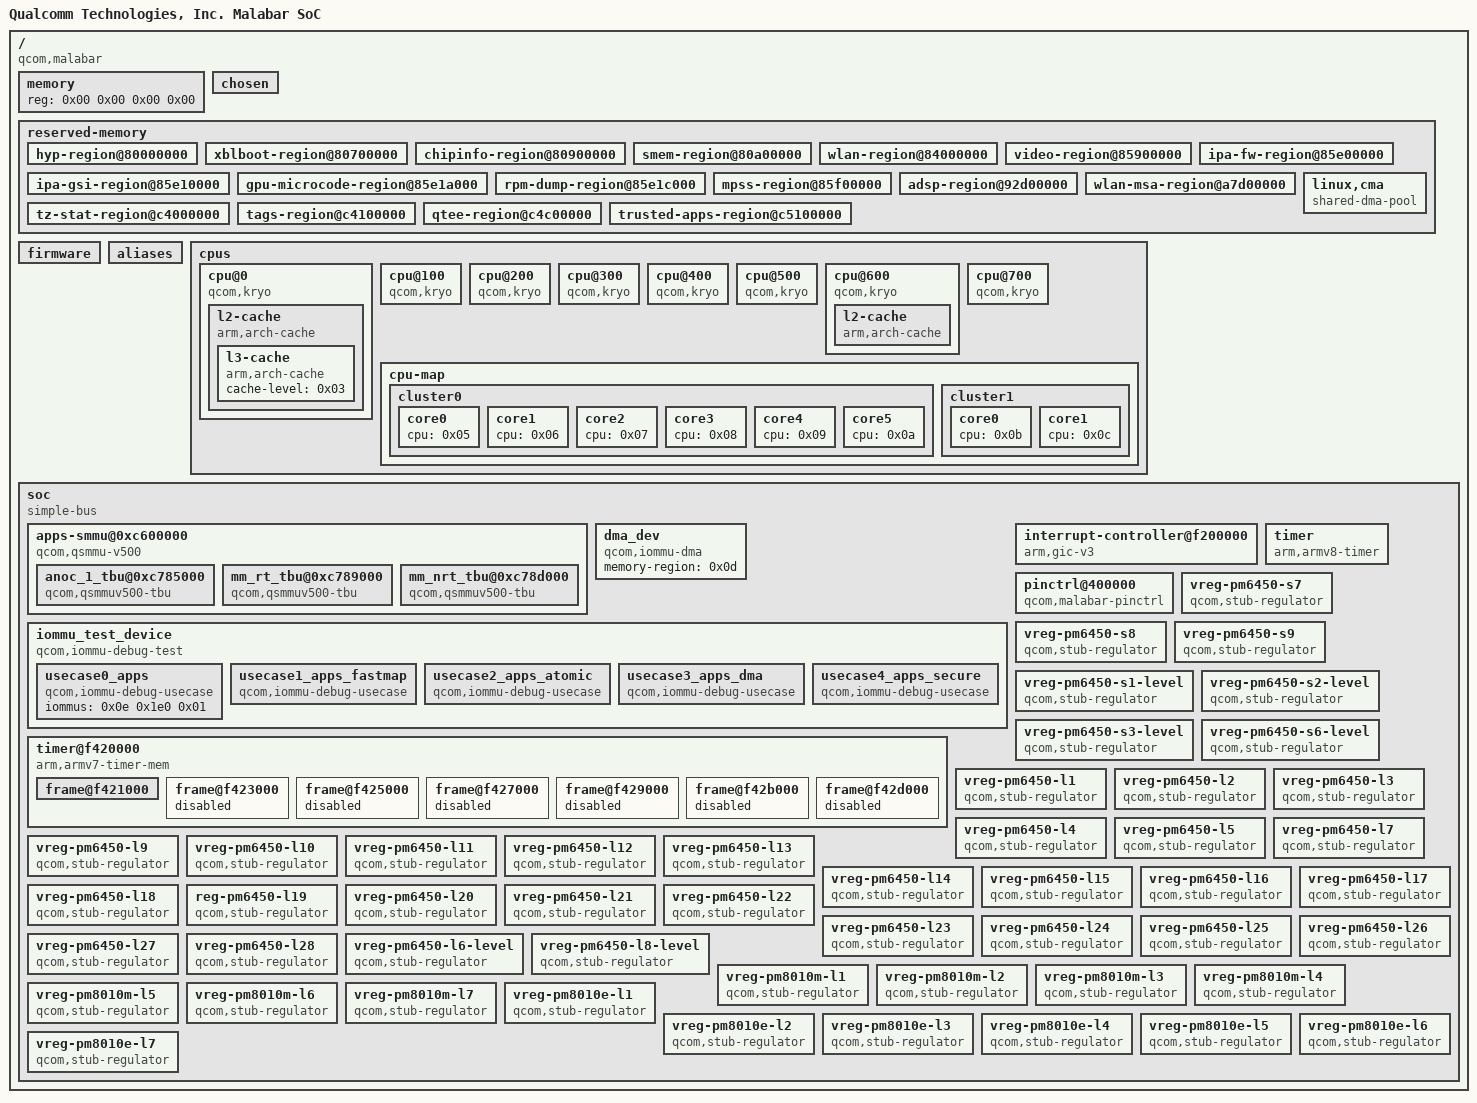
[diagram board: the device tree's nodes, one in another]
/dts-v1/;

/ {
	model = "Qualcomm Technologies, Inc. Malabar SoC";
	compatible = "qcom,malabar";
	qcom,msm-id = <0x2dd 0x10000>;
	interrupt-parent = <0x01>;
	#address-cells = <0x02>;
	#size-cells = <0x02>;
	qcom,board-id = <0x00 0x00>;

	memory {
		device_type = "memory";
		reg = <0x00 0x00 0x00 0x00>;
	};

	chosen {
		bootargs = "nokaslr kpti=0 log_buf_len=256K swiotlb=0 loop.max_part=7";
		phandle = <0x0f>;
	};

	reserved-memory {
		#address-cells = <0x02>;
		#size-cells = <0x02>;
		ranges;
		phandle = <0x10>;

		hyp-region@80000000 {
			reg = <0x00 0x80000000 0x00 0x700000>;
			no-map;
			phandle = <0x11>;
		};

		xblboot-region@80700000 {
			reg = <0x00 0x80700000 0x00 0x100000>;
			no-map;
			phandle = <0x12>;
		};

		chipinfo-region@80900000 {
			reg = <0x00 0x80900000 0x00 0x1000>;
			no-map;
			phandle = <0x13>;
		};

		smem-region@80a00000 {
			reg = <0x00 0x80a00000 0x00 0x200000>;
			no-map;
			phandle = <0x14>;
		};

		wlan-region@84000000 {
			reg = <0x00 0x84000000 0x00 0x1900000>;
			no-map;
			phandle = <0x15>;
		};

		video-region@85900000 {
			reg = <0x00 0x85900000 0x00 0x500000>;
			no-map;
			phandle = <0x16>;
		};

		ipa-fw-region@85e00000 {
			reg = <0x00 0x85e00000 0x00 0x10000>;
			no-map;
			phandle = <0x17>;
		};

		ipa-gsi-region@85e10000 {
			reg = <0x00 0x85e10000 0x00 0xa000>;
			no-map;
			phandle = <0x18>;
		};

		gpu-microcode-region@85e1a000 {
			reg = <0x00 0x85e1a000 0x00 0x2000>;
			no-map;
			phandle = <0x19>;
		};

		rpm-dump-region@85e1c000 {
			reg = <0x00 0x85e1c000 0x00 0x25800>;
			no-map;
			phandle = <0x1a>;
		};

		mpss-region@85f00000 {
			reg = <0x00 0x85f00000 0x00 0xce00000>;
			no-map;
			phandle = <0x1b>;
		};

		adsp-region@92d00000 {
			reg = <0x00 0x92d00000 0x00 0x1e00000>;
			no-map;
			phandle = <0x1c>;
		};

		wlan-msa-region@a7d00000 {
			reg = <0x00 0xa7d00000 0x00 0x300000>;
			no-map;
			phandle = <0x1d>;
		};

		tz-stat-region@c4000000 {
			reg = <0x00 0xc4000000 0x00 0x100000>;
			no-map;
			phandle = <0x1e>;
		};

		tags-region@c4100000 {
			reg = <0x00 0xc4100000 0x00 0xb00000>;
			no-map;
			phandle = <0x1f>;
		};

		qtee-region@c4c00000 {
			reg = <0x00 0xc4c00000 0x00 0x500000>;
			no-map;
			phandle = <0x20>;
		};

		trusted-apps-region@c5100000 {
			reg = <0x00 0xc5100000 0x00 0x2100000>;
			no-map;
			phandle = <0x21>;
		};

		linux,cma {
			compatible = "shared-dma-pool";
			alloc-ranges = <0x00 0x00 0x00 0xffffffff>;
			reusable;
			alignment = <0x00 0x400000>;
			size = <0x00 0x2400000>;
			linux,cma-default;
			phandle = <0x0d>;
		};
	};

	firmware {
		phandle = <0x22>;
	};

	aliases {
	};

	cpus {
		#address-cells = <0x02>;
		#size-cells = <0x00>;

		cpu@0 {
			device_type = "cpu";
			compatible = "qcom,kryo";
			reg = <0x00 0x00>;
			enable-method = "spin-table";
			cpu-release-addr = <0x00 0xe3940000>;
			next-level-cache = <0x02>;
			phandle = <0x05>;

			l2-cache {
				compatible = "arm,arch-cache";
				cache-level = <0x02>;
				next-level-cache = <0x03>;
				phandle = <0x02>;

				l3-cache {
					compatible = "arm,arch-cache";
					cache-level = <0x03>;
					phandle = <0x03>;
				};
			};
		};

		cpu@100 {
			device_type = "cpu";
			compatible = "qcom,kryo";
			reg = <0x00 0x100>;
			enable-method = "spin-table";
			cpu-release-addr = <0x00 0xe3940000>;
			next-level-cache = <0x02>;
			phandle = <0x06>;
		};

		cpu@200 {
			device_type = "cpu";
			compatible = "qcom,kryo";
			reg = <0x00 0x200>;
			enable-method = "spin-table";
			cpu-release-addr = <0x00 0xe3940000>;
			next-level-cache = <0x02>;
			phandle = <0x07>;
		};

		cpu@300 {
			device_type = "cpu";
			compatible = "qcom,kryo";
			reg = <0x00 0x300>;
			enable-method = "spin-table";
			cpu-release-addr = <0x00 0xe3940000>;
			next-level-cache = <0x02>;
			phandle = <0x08>;
		};

		cpu@400 {
			device_type = "cpu";
			compatible = "qcom,kryo";
			reg = <0x00 0x400>;
			enable-method = "spin-table";
			cpu-release-addr = <0x00 0xe3940000>;
			next-level-cache = <0x02>;
			phandle = <0x09>;
		};

		cpu@500 {
			device_type = "cpu";
			compatible = "qcom,kryo";
			reg = <0x00 0x500>;
			enable-method = "spin-table";
			cpu-release-addr = <0x00 0xe3940000>;
			next-level-cache = <0x02>;
			phandle = <0x0a>;
		};

		cpu@600 {
			device_type = "cpu";
			compatible = "qcom,kryo";
			reg = <0x00 0x600>;
			enable-method = "spin-table";
			cpu-release-addr = <0x00 0xe3940000>;
			next-level-cache = <0x04>;
			phandle = <0x0b>;

			l2-cache {
				compatible = "arm,arch-cache";
				cache-level = <0x02>;
				next-level-cache = <0x03>;
				phandle = <0x04>;
			};
		};

		cpu@700 {
			device_type = "cpu";
			compatible = "qcom,kryo";
			reg = <0x00 0x700>;
			enable-method = "spin-table";
			cpu-release-addr = <0x00 0xe3940000>;
			next-level-cache = <0x04>;
			phandle = <0x0c>;
		};

		cpu-map {

			cluster0 {

				core0 {
					cpu = <0x05>;
				};

				core1 {
					cpu = <0x06>;
				};

				core2 {
					cpu = <0x07>;
				};

				core3 {
					cpu = <0x08>;
				};

				core4 {
					cpu = <0x09>;
				};

				core5 {
					cpu = <0x0a>;
				};
			};

			cluster1 {

				core0 {
					cpu = <0x0b>;
				};

				core1 {
					cpu = <0x0c>;
				};
			};
		};
	};

	soc {
		#address-cells = <0x01>;
		#size-cells = <0x01>;
		ranges = <0x00 0x00 0x00 0xffffffff>;
		compatible = "simple-bus";
		phandle = <0x23>;

		apps-smmu@0xc600000 {
			compatible = "qcom,qsmmu-v500";
			reg = <0xc600000 0x80000 0xc782000 0x20>;
			reg-names = "base\0tcu-base";
			#iommu-cells = <0x02>;
			qcom,use-3-lvl-tables;
			qcom,handoff-smrs = <0x420 0x02>;
			#global-interrupts = <0x01>;
			#size-cells = <0x01>;
			#address-cells = <0x01>;
			ranges;
			interrupts = <0x00 0x51 0x04 0x00 0x57 0x04 0x00 0x58 0x04 0x00 0x59 0x04 0x00 0x5a 0x04 0x00 0x5b 0x04 0x00 0x5c 0x04 0x00 0x5d 0x04 0x00 0x5e 0x04 0x00 0x5f 0x04 0x00 0x60 0x04 0x00 0x61 0x04 0x00 0x62 0x04 0x00 0x63 0x04 0x00 0x64 0x04 0x00 0x65 0x04 0x00 0x66 0x04 0x00 0x67 0x04 0x00 0x68 0x04 0x00 0x69 0x04 0x00 0x6a 0x04 0x00 0x6b 0x04 0x00 0x6c 0x04 0x00 0x6d 0x04 0x00 0x6e 0x04 0x00 0x6f 0x04 0x00 0x70 0x04 0x00 0x71 0x04 0x00 0x72 0x04 0x00 0x73 0x04 0x00 0x74 0x04 0x00 0x75 0x04 0x00 0x76 0x04 0x00 0x77 0x04 0x00 0x78 0x04 0x00 0x79 0x04 0x00 0x7a 0x04 0x00 0x7b 0x04 0x00 0x7c 0x04 0x00 0x7d 0x04 0x00 0x7e 0x04 0x00 0x7f 0x04 0x00 0x80 0x04 0x00 0x81 0x04 0x00 0x82 0x04 0x00 0x83 0x04 0x00 0x84 0x04 0x00 0x85 0x04 0x00 0x86 0x04 0x00 0x87 0x04 0x00 0x88 0x04 0x00 0x89 0x04 0x00 0x8a 0x04 0x00 0x8b 0x04 0x00 0x8c 0x04 0x00 0x8d 0x04 0x00 0x8e 0x04 0x00 0x8f 0x04 0x00 0x90 0x04 0x00 0x91 0x04 0x00 0x92 0x04 0x00 0x93 0x04 0x00 0x94 0x04 0x00 0x95 0x04 0x00 0x96 0x04>;
			phandle = <0x0e>;

			anoc_1_tbu@0xc785000 {
				compatible = "qcom,qsmmuv500-tbu";
				reg = <0xc785000 0x1000 0xc782200 0x08>;
				reg-names = "base\0status-reg";
				qcom,stream-id-range = <0x00 0x400>;
				qcom,iova-width = <0x24>;
				phandle = <0x24>;
			};

			mm_rt_tbu@0xc789000 {
				compatible = "qcom,qsmmuv500-tbu";
				reg = <0xc789000 0x1000 0xc782208 0x08>;
				reg-names = "base\0status-reg";
				qcom,stream-id-range = <0x400 0x400>;
				qcom,iova-width = <0x24>;
				phandle = <0x25>;
			};

			mm_nrt_tbu@0xc78d000 {
				compatible = "qcom,qsmmuv500-tbu";
				reg = <0xc78d000 0x1000 0xc782210 0x08>;
				reg-names = "base\0status-reg";
				qcom,stream-id-range = <0x800 0x400>;
				qcom,iova-width = <0x20>;
				phandle = <0x26>;
			};
		};

		dma_dev {
			compatible = "qcom,iommu-dma";
			memory-region = <0x0d>;
		};

		iommu_test_device {
			compatible = "qcom,iommu-debug-test";

			usecase0_apps {
				compatible = "qcom,iommu-debug-usecase";
				iommus = <0x0e 0x1e0 0x01>;
			};

			usecase1_apps_fastmap {
				compatible = "qcom,iommu-debug-usecase";
				iommus = <0x0e 0x1e0 0x01>;
				qcom,iommu-dma = "fastmap";
			};

			usecase2_apps_atomic {
				compatible = "qcom,iommu-debug-usecase";
				iommus = <0x0e 0x1e0 0x01>;
				qcom,iommu-dma = "atomic";
			};

			usecase3_apps_dma {
				compatible = "qcom,iommu-debug-usecase";
				iommus = <0x0e 0x1e0 0x01>;
				dma-coherent;
			};

			usecase4_apps_secure {
				compatible = "qcom,iommu-debug-usecase";
				iommus = <0x0e 0x1e0 0x01>;
				qcom,iommu-vmid = <0x0a>;
			};
		};

		interrupt-controller@f200000 {
			compatible = "arm,gic-v3";
			#interrupt-cells = <0x03>;
			interrupt-controller;
			#redistributor-regions = <0x01>;
			redistributor-stride = <0x00 0x20000>;
			reg = <0xf200000 0x10000 0xf240000 0x100000>;
			interrupts = <0x01 0x08 0x04>;
			phandle = <0x01>;
		};

		timer {
			compatible = "arm,armv8-timer";
			interrupts = <0x01 0x01 0xff08 0x01 0x02 0xff08 0x01 0x03 0xff08 0x01 0x00 0xff08>;
			clock-frequency = <0x124f800>;
			phandle = <0x27>;
		};

		timer@f420000 {
			#address-cells = <0x01>;
			#size-cells = <0x01>;
			ranges;
			compatible = "arm,armv7-timer-mem";
			reg = <0xf420000 0x1000>;
			clock-frequency = <0x124f800>;
			phandle = <0x28>;

			frame@f421000 {
				frame-number = <0x00>;
				interrupts = <0x00 0x08 0x04 0x00 0x06 0x04>;
				reg = <0xf421000 0x1000 0xf422000 0x1000>;
			};

			frame@f423000 {
				frame-number = <0x01>;
				interrupts = <0x00 0x09 0x04>;
				reg = <0xf243000 0x1000>;
				status = "disabled";
			};

			frame@f425000 {
				frame-number = <0x02>;
				interrupts = <0x00 0x0a 0x04>;
				reg = <0xf425000 0x1000>;
				status = "disabled";
			};

			frame@f427000 {
				frame-number = <0x03>;
				interrupts = <0x00 0x0b 0x04>;
				reg = <0xf427000 0x1000>;
				status = "disabled";
			};

			frame@f429000 {
				frame-number = <0x04>;
				interrupts = <0x00 0x0c 0x04>;
				reg = <0xf429000 0x1000>;
				status = "disabled";
			};

			frame@f42b000 {
				frame-number = <0x05>;
				interrupts = <0x00 0x0d 0x04>;
				reg = <0xf42b000 0x1000>;
				status = "disabled";
			};

			frame@f42d000 {
				frame-number = <0x06>;
				interrupts = <0x00 0x0e 0x04>;
				reg = <0xf42d000 0x1000>;
				status = "disabled";
			};
		};

		pinctrl@400000 {
			compatible = "qcom,malabar-pinctrl";
			reg = <0x400000 0x1000000>;
			interrupts = <0x00 0xe3 0x04>;
			gpio-controller;
			#gpio-cells = <0x02>;
			interrupt-controller;
			#interrupt-cells = <0x02>;
			phandle = <0x29>;
		};

		vreg-pm6450-s7 {
			compatible = "qcom,stub-regulator";
			regulator-name = "pm6450_s7";
			qcom,hpm-min-load = <0x2710>;
			regulator-min-microvolt = <0x102ca0>;
			regulator-max-microvolt = <0x11da50>;
			phandle = <0x2a>;
		};

		vreg-pm6450-s8 {
			compatible = "qcom,stub-regulator";
			regulator-name = "pm6450_s8";
			qcom,hpm-min-load = <0x2710>;
			regulator-min-microvolt = <0x8c230>;
			regulator-max-microvolt = <0x14f730>;
			phandle = <0x2b>;
		};

		vreg-pm6450-s9 {
			compatible = "qcom,stub-regulator";
			regulator-name = "pm6450_s9";
			qcom,hpm-min-load = <0x2710>;
			regulator-min-microvolt = <0x1c5200>;
			regulator-max-microvolt = <0x1f20c0>;
			phandle = <0x2c>;
		};

		vreg-pm6450-s1-level {
			compatible = "qcom,stub-regulator";
			regulator-name = "pm_pm6450_s1_level";
			qcom,hpm-min-load = <0x2710>;
			regulator-min-microvolt = <0x10>;
			regulator-max-microvolt = <0xffff>;
			phandle = <0x2d>;
		};

		vreg-pm6450-s2-level {
			compatible = "qcom,stub-regulator";
			regulator-name = "pm6450_s2_level";
			qcom,hpm-min-load = <0x2710>;
			regulator-min-microvolt = <0x10>;
			regulator-max-microvolt = <0xffff>;
			phandle = <0x2e>;
		};

		vreg-pm6450-s3-level {
			compatible = "qcom,stub-regulator";
			regulator-name = "pm6450_s3_level";
			qcom,hpm-min-load = <0x2710>;
			regulator-min-microvolt = <0x10>;
			regulator-max-microvolt = <0xffff>;
			phandle = <0x2f>;
		};

		vreg-pm6450-s6-level {
			compatible = "qcom,stub-regulator";
			regulator-name = "pm6450_s6_level";
			qcom,hpm-min-load = <0x2710>;
			regulator-min-microvolt = <0x10>;
			regulator-max-microvolt = <0xffff>;
			phandle = <0x30>;
		};

		vreg-pm6450-l1 {
			compatible = "qcom,stub-regulator";
			regulator-name = "pm6450_l1";
			qcom,hpm-min-load = <0x2710>;
			regulator-min-microvolt = <0x8b290>;
			regulator-max-microvolt = <0x9eb10>;
			phandle = <0x31>;
		};

		vreg-pm6450-l2 {
			compatible = "qcom,stub-regulator";
			regulator-name = "pm6450_l2";
			qcom,hpm-min-load = <0x2710>;
			regulator-min-microvolt = <0x4c2c0>;
			regulator-max-microvolt = <0xb7980>;
			phandle = <0x32>;
		};

		vreg-pm6450-l3 {
			compatible = "qcom,stub-regulator";
			regulator-name = "pm6450_l3";
			qcom,hpm-min-load = <0x2710>;
			regulator-min-microvolt = <0x102ca0>;
			regulator-max-microvolt = <0x11da50>;
			phandle = <0x33>;
		};

		vreg-pm6450-l4 {
			compatible = "qcom,stub-regulator";
			regulator-name = "pm6450_l4";
			qcom,hpm-min-load = <0x2710>;
			regulator-min-microvolt = <0x81650>;
			regulator-max-microvolt = "\0\r/";
			phandle = <0x34>;
		};

		vreg-pm6450-l5 {
			compatible = "qcom,stub-regulator";
			regulator-name = "pm6450_l5";
			qcom,hpm-min-load = <0x2710>;
			regulator-min-microvolt = <0x4c2c0>;
			regulator-max-microvolt = <0xe86c0>;
			phandle = <0x35>;
		};

		vreg-pm6450-l7 {
			compatible = "qcom,stub-regulator";
			regulator-name = "pm6450_l7";
			qcom,hpm-min-load = <0x2710>;
			regulator-min-microvolt = <0x4c2c0>;
			regulator-max-microvolt = <0x13e5c0>;
			phandle = <0x36>;
		};

		vreg-pm6450-l9 {
			compatible = "qcom,stub-regulator";
			regulator-name = "pm6450_l9";
			qcom,hpm-min-load = <0x2710>;
			regulator-min-microvolt = <0xb7598>;
			regulator-max-microvolt = <0xc92c0>;
			phandle = <0x37>;
		};

		vreg-pm6450-l10 {
			compatible = "qcom,stub-regulator";
			regulator-name = "pm6450_l10";
			qcom,hpm-min-load = <0x2710>;
			regulator-min-microvolt = <0xc92c0>;
			regulator-max-microvolt = <0xe7ef0>;
			phandle = <0x38>;
		};

		vreg-pm6450-l11 {
			compatible = "qcom,stub-regulator";
			regulator-name = "pm6450_l11";
			qcom,hpm-min-load = <0x2710>;
			regulator-min-microvolt = <0x4c2c0>;
			regulator-max-microvolt = <0x13e5c0>;
			phandle = <0x39>;
		};

		vreg-pm6450-l12 {
			compatible = "qcom,stub-regulator";
			regulator-name = "pm6450_l12";
			qcom,hpm-min-load = <0x2710>;
			regulator-min-microvolt = <0x107ac0>;
			regulator-max-microvolt = <0x13e5c0>;
			phandle = <0x3a>;
		};

		vreg-pm6450-l13 {
			compatible = "qcom,stub-regulator";
			regulator-name = "pm6450_l13";
			qcom,hpm-min-load = <0x2710>;
			regulator-min-microvolt = <0x107ac0>;
			regulator-max-microvolt = <0x13e5c0>;
			phandle = <0x3b>;
		};

		vreg-pm6450-l14 {
			compatible = "qcom,stub-regulator";
			regulator-name = "pm6450_l14";
			qcom,hpm-min-load = <0x2710>;
			regulator-min-microvolt = <0x118c30>;
			regulator-max-microvolt = <0x13e5c0>;
			phandle = <0x3c>;
		};

		vreg-pm6450-l15 {
			compatible = "qcom,stub-regulator";
			regulator-name = "pm6450_l15";
			qcom,hpm-min-load = <0x2710>;
			regulator-min-microvolt = <0x124f80>;
			regulator-max-microvolt = <0x13e5c0>;
			phandle = <0x3d>;
		};

		vreg-pm6450-l16 {
			compatible = "qcom,stub-regulator";
			regulator-name = "pm6450_l16";
			qcom,hpm-min-load = <0x2710>;
			regulator-min-microvolt = <0x116520>;
			regulator-max-microvolt = <0x1339e0>;
			phandle = <0x3e>;
		};

		vreg-pm6450-l17 {
			compatible = "qcom,stub-regulator";
			regulator-name = "pm6450_l17";
			qcom,hpm-min-load = <0x2710>;
			regulator-min-microvolt = <0x11da50>;
			regulator-max-microvolt = <0x13e5c0>;
			phandle = <0x3f>;
		};

		vreg-pm6450-l18 {
			compatible = "qcom,stub-regulator";
			regulator-name = "pm6450_l18";
			qcom,hpm-min-load = <0x2710>;
			regulator-min-microvolt = <0x16f300>;
			regulator-max-microvolt = <0x1e8480>;
			phandle = <0x40>;
		};

		reg-pm6450-l19 {
			compatible = "qcom,stub-regulator";
			regulator-name = "pm6450_l19";
			qcom,hpm-min-load = <0x2710>;
			regulator-min-microvolt = <0x19f0a0>;
			regulator-max-microvolt = <0x1dc130>;
			phandle = <0x41>;
		};

		vreg-pm6450-l20 {
			compatible = "qcom,stub-regulator";
			regulator-name = "pm6450_l20";
			qcom,hpm-min-load = <0x2710>;
			regulator-min-microvolt = <0x19f0a0>;
			regulator-max-microvolt = <0x1cfde0>;
			phandle = <0x42>;
		};

		vreg-pm6450-l21 {
			compatible = "qcom,stub-regulator";
			regulator-name = "pm6450_l21";
			qcom,hpm-min-load = <0x2710>;
			regulator-min-microvolt = <0x16f300>;
			regulator-max-microvolt = <0x1e8480>;
			phandle = <0x43>;
		};

		vreg-pm6450-l22 {
			compatible = "qcom,stub-regulator";
			regulator-name = "pm6450_l22";
			qcom,hpm-min-load = <0x2710>;
			regulator-min-microvolt = <0x16f300>;
			regulator-max-microvolt = <0x1e8480>;
			phandle = <0x44>;
		};

		vreg-pm6450-l23 {
			compatible = "qcom,stub-regulator";
			regulator-name = "pm6450_l23";
			qcom,hpm-min-load = <0x2710>;
			regulator-min-microvolt = <0x16f300>;
			regulator-max-microvolt = <0x1e8480>;
			phandle = <0x45>;
		};

		vreg-pm6450-l24 {
			compatible = "qcom,stub-regulator";
			regulator-name = "pm6450_l24";
			qcom,hpm-min-load = <0x2710>;
			regulator-min-microvolt = <0x2932e0>;
			regulator-max-microvolt = <0x3613c0>;
			phandle = <0x46>;
		};

		vreg-pm6450-l25 {
			compatible = "qcom,stub-regulator";
			regulator-name = "pm6450_l25";
			qcom,hpm-min-load = <0x2710>;
			regulator-min-microvolt = <0x2932e0>;
			regulator-max-microvolt = <0x3613c0>;
			phandle = <0x47>;
		};

		vreg-pm6450-l26 {
			compatible = "qcom,stub-regulator";
			regulator-name = "pm6450_l26";
			qcom,hpm-min-load = <0x2710>;
			regulator-min-microvolt = <0x16f300>;
			regulator-max-microvolt = <0x325aa0>;
			phandle = <0x48>;
		};

		vreg-pm6450-l27 {
			compatible = "qcom,stub-regulator";
			regulator-name = "pm6450_l27";
			qcom,hpm-min-load = <0x2710>;
			regulator-min-microvolt = <0x16f300>;
			regulator-max-microvolt = <0x325aa0>;
			phandle = <0x49>;
		};

		vreg-pm6450-l28 {
			compatible = "qcom,stub-regulator";
			regulator-name = "pm6450_l28";
			qcom,hpm-min-load = <0x2710>;
			regulator-min-microvolt = <0x192d50>;
			regulator-max-microvolt = <0x325aa0>;
			phandle = <0x4a>;
		};

		vreg-pm6450-l6-level {
			compatible = "qcom,stub-regulator";
			regulator-name = "pm6450_l6_level";
			qcom,hpm-min-load = <0x2710>;
			regulator-min-microvolt = <0x10>;
			regulator-max-microvolt = <0xffff>;
			phandle = <0x4b>;
		};

		vreg-pm6450-l8-level {
			compatible = "qcom,stub-regulator";
			regulator-name = "pm6450_l8_level";
			qcom,hpm-min-load = <0x2710>;
			regulator-min-microvolt = <0x10>;
			regulator-max-microvolt = <0xffff>;
			phandle = <0x4c>;
		};

		vreg-pm8010m-l1 {
			compatible = "qcom,stub-regulator";
			regulator-name = "pm8010m_l1";
			qcom,hpm-min-load = <0x2710>;
			regulator-min-microvolt = <0xf4240>;
			regulator-max-microvolt = <0x124f80>;
			phandle = <0x4d>;
		};

		vreg-pm8010m-l2 {
			compatible = "qcom,stub-regulator";
			regulator-name = "pm8010m_l2";
			qcom,hpm-min-load = <0x2710>;
			regulator-min-microvolt = <0xe7ef0>;
			regulator-max-microvolt = <0x118c30>;
			phandle = <0x4e>;
		};

		vreg-pm8010m-l3 {
			compatible = "qcom,stub-regulator";
			regulator-name = "pm8010m_l3";
			qcom,hpm-min-load = <0x2710>;
			regulator-min-microvolt = <0x2932e0>;
			regulator-max-microvolt = <0x2c4020>;
			phandle = <0x4f>;
		};

		vreg-pm8010m-l4 {
			compatible = "qcom,stub-regulator";
			regulator-name = "pm8010m_l4";
			qcom,hpm-min-load = <0x2710>;
			regulator-min-microvolt = <0x2932e0>;
			regulator-max-microvolt = <0x2c4020>;
			phandle = <0x50>;
		};

		vreg-pm8010m-l5 {
			compatible = "qcom,stub-regulator";
			regulator-name = "pm8010m_l5";
			qcom,hpm-min-load = <0x2710>;
			regulator-min-microvolt = <0x16f300>;
			regulator-max-microvolt = <0x1cfde0>;
			phandle = <0x51>;
		};

		vreg-pm8010m-l6 {
			compatible = "qcom,stub-regulator";
			regulator-name = "pm8010m_l6";
			qcom,hpm-min-load = <0x2710>;
			regulator-min-microvolt = <0x2932e0>;
			regulator-max-microvolt = <0x2dc6c0>;
			phandle = <0x52>;
		};

		vreg-pm8010m-l7 {
			compatible = "qcom,stub-regulator";
			regulator-name = "pm8010m_l7";
			qcom,hpm-min-load = <0x2710>;
			regulator-min-microvolt = <0x2932e0>;
			regulator-max-microvolt = <0x2c4020>;
			phandle = <0x53>;
		};

		vreg-pm8010e-l1 {
			compatible = "qcom,stub-regulator";
			regulator-name = "pm8010e_l1";
			qcom,hpm-min-load = <0x2710>;
			regulator-min-microvolt = <0x80e80>;
			regulator-max-microvolt = <0x178f40>;
			phandle = <0x54>;
		};

		vreg-pm8010e-l2 {
			compatible = "qcom,stub-regulator";
			regulator-name = "pm8010e_l2";
			qcom,hpm-min-load = <0x2710>;
			regulator-min-microvolt = <0x80e80>;
			regulator-max-microvolt = <0x178f40>;
			phandle = <0x55>;
		};

		vreg-pm8010e-l3 {
			compatible = "qcom,stub-regulator";
			regulator-name = "pm8010e_l3";
			qcom,hpm-min-load = <0x2710>;
			regulator-min-microvolt = <0x1b5800>;
			regulator-max-microvolt = <0x328980>;
			phandle = <0x56>;
		};

		vreg-pm8010e-l4 {
			compatible = "qcom,stub-regulator";
			regulator-name = "pm8010e_l4";
			qcom,hpm-min-load = <0x2710>;
			regulator-min-microvolt = <0x27ac40>;
			regulator-max-microvolt = <0x328980>;
			phandle = <0x57>;
		};

		vreg-pm8010e-l5 {
			compatible = "qcom,stub-regulator";
			regulator-name = "pm8010e_l5";
			qcom,hpm-min-load = <0x2710>;
			regulator-min-microvolt = <0x249f00>;
			regulator-max-microvolt = <0x3613c0>;
			phandle = <0x58>;
		};

		vreg-pm8010e-l6 {
			compatible = "qcom,stub-regulator";
			regulator-name = "pm8010e_l6";
			qcom,hpm-min-load = <0x2710>;
			regulator-min-microvolt = <0x2dc6c0>;
			regulator-max-microvolt = <0x328980>;
			phandle = <0x59>;
		};

		vreg-pm8010e-l7 {
			compatible = "qcom,stub-regulator";
			regulator-name = "pm8010e_l7";
			qcom,hpm-min-load = <0x2710>;
			regulator-min-microvolt = <0x2625a0>;
			regulator-max-microvolt = <0x3613c0>;
			phandle = <0x5a>;
		};
	};

	__symbols__ {
		chosen = "/chosen";
		reserved_memory = "/reserved-memory";
		hyp_mem = "/reserved-memory/hyp-region@80000000";
		xblboot_mem = "/reserved-memory/xblboot-region@80700000";
		chipinfo_mem = "/reserved-memory/chipinfo-region@80900000";
		smem_mem = "/reserved-memory/smem-region@80a00000";
		wlan_mem = "/reserved-memory/wlan-region@84000000";
		video_mem = "/reserved-memory/video-region@85900000";
		ipa_fw_mem = "/reserved-memory/ipa-fw-region@85e00000";
		ipa_gsi_mem = "/reserved-memory/ipa-gsi-region@85e10000";
		gpu_microcode_mem = "/reserved-memory/gpu-microcode-region@85e1a000";
		rpm_dump_mem = "/reserved-memory/rpm-dump-region@85e1c000";
		mpss_mem = "/reserved-memory/mpss-region@85f00000";
		adsp_mem = "/reserved-memory/adsp-region@92d00000";
		wlan_msa_mem = "/reserved-memory/wlan-msa-region@a7d00000";
		tz_stat_mem = "/reserved-memory/tz-stat-region@c4000000";
		tags_mem = "/reserved-memory/tags-region@c4100000";
		qtee_mem = "/reserved-memory/qtee-region@c4c00000";
		trusted_apps_mem = "/reserved-memory/trusted-apps-region@c5100000";
		system_cma = "/reserved-memory/linux,cma";
		firmware = "/firmware";
		CPU0 = "/cpus/cpu@0";
		L2_0 = "/cpus/cpu@0/l2-cache";
		L3_0 = "/cpus/cpu@0/l2-cache/l3-cache";
		CPU1 = "/cpus/cpu@100";
		CPU2 = "/cpus/cpu@200";
		CPU3 = "/cpus/cpu@300";
		CPU4 = "/cpus/cpu@400";
		CPU5 = "/cpus/cpu@500";
		CPU6 = "/cpus/cpu@600";
		L2_6 = "/cpus/cpu@600/l2-cache";
		CPU7 = "/cpus/cpu@700";
		soc = "/soc";
		apps_smmu = "/soc/apps-smmu@0xc600000";
		anoc_1_tbu = "/soc/apps-smmu@0xc600000/anoc_1_tbu@0xc785000";
		mm_rt_tbu = "/soc/apps-smmu@0xc600000/mm_rt_tbu@0xc789000";
		mm_nrt_tbu = "/soc/apps-smmu@0xc600000/mm_nrt_tbu@0xc78d000";
		intc = "/soc/interrupt-controller@f200000";
		arch_timer = "/soc/timer";
		memtimer = "/soc/timer@f420000";
		tlmm = "/soc/pinctrl@400000";
		S7B = "/soc/vreg-pm6450-s7";
		S7B_E0 = "/soc/vreg-pm6450-s7";
		pm6450_s7 = "/soc/vreg-pm6450-s7";
		S8B = "/soc/vreg-pm6450-s8";
		S8B_E0 = "/soc/vreg-pm6450-s8";
		pm6450_s8 = "/soc/vreg-pm6450-s8";
		S9B = "/soc/vreg-pm6450-s9";
		S9B_E0 = "/soc/vreg-pm6450-s9";
		pm6450_s9 = "/soc/vreg-pm6450-s9";
		VDD_MODEM_LEVEL = "/soc/vreg-pm6450-s1-level";
		S1B_LEVEL = "/soc/vreg-pm6450-s1-level";
		S1B_E0_LEVEL = "/soc/vreg-pm6450-s1-level";
		pm6450_s1_level = "/soc/vreg-pm6450-s1-level";
		VDD_CX_LEVEL = "/soc/vreg-pm6450-s2-level";
		S2B_LEVEL = "/soc/vreg-pm6450-s2-level";
		S2B_E0_LEVEL = "/soc/vreg-pm6450-s2-level";
		VDD_CX_LEVEL_AO = "/soc/vreg-pm6450-s2-level";
		S2B_LEVEL_AO = "/soc/vreg-pm6450-s2-level";
		S2B_E0_LEVEL_A0 = "/soc/vreg-pm6450-s2-level";
		pm6450_s2_level = "/soc/vreg-pm6450-s2-level";
		VDD_GFX_LEVEL = "/soc/vreg-pm6450-s3-level";
		S3B_LEVEL = "/soc/vreg-pm6450-s3-level";
		S3B_E0_LEVEL = "/soc/vreg-pm6450-s3-level";
		pm6450_s3_level = "/soc/vreg-pm6450-s3-level";
		VDD_MX_LEVEL = "/soc/vreg-pm6450-s6-level";
		S6B_LEVEL = "/soc/vreg-pm6450-s6-level";
		S6B_E0_LEVEL = "/soc/vreg-pm6450-s6-level";
		VDD_MX_LEVEL_AO = "/soc/vreg-pm6450-s6-level";
		S6B_LEVEL_AO = "/soc/vreg-pm6450-s6-level";
		pm6450_s6_level = "/soc/vreg-pm6450-s6-level";
		L1B = "/soc/vreg-pm6450-l1";
		L1B_E0 = "/soc/vreg-pm6450-l1";
		pm6450_l1 = "/soc/vreg-pm6450-l1";
		L2B = "/soc/vreg-pm6450-l2";
		L2B_E0 = "/soc/vreg-pm6450-l2";
		pm6450_l2 = "/soc/vreg-pm6450-l2";
		L3B = "/soc/vreg-pm6450-l3";
		L3B_E0 = "/soc/vreg-pm6450-l3";
		pm6450_l3 = "/soc/vreg-pm6450-l3";
		L4B = "/soc/vreg-pm6450-l4";
		L4B_E0 = "/soc/vreg-pm6450-l4";
		pm6450_l4 = "/soc/vreg-pm6450-l4";
		L5B = "/soc/vreg-pm6450-l5";
		L5B_E0 = "/soc/vreg-pm6450-l5";
		pm6450_l5 = "/soc/vreg-pm6450-l5";
		L7B = "/soc/vreg-pm6450-l7";
		L7B_E0 = "/soc/vreg-pm6450-l7";
		pm6450_l7 = "/soc/vreg-pm6450-l7";
		L9B = "/soc/vreg-pm6450-l9";
		L9B_E0 = "/soc/vreg-pm6450-l9";
		pm6450_l9 = "/soc/vreg-pm6450-l9";
		L10B = "/soc/vreg-pm6450-l10";
		L10B_E0 = "/soc/vreg-pm6450-l10";
		pm6450_l10 = "/soc/vreg-pm6450-l10";
		L11B = "/soc/vreg-pm6450-l11";
		L11B_E0 = "/soc/vreg-pm6450-l11";
		pm6450_l11 = "/soc/vreg-pm6450-l11";
		L12B = "/soc/vreg-pm6450-l12";
		L12B_E0 = "/soc/vreg-pm6450-l12";
		pm6450_l12 = "/soc/vreg-pm6450-l12";
		L13B = "/soc/vreg-pm6450-l13";
		L13B_E0 = "/soc/vreg-pm6450-l13";
		pm6450_l13 = "/soc/vreg-pm6450-l13";
		L14B = "/soc/vreg-pm6450-l14";
		L14B_E0 = "/soc/vreg-pm6450-l14";
		pm6450_l14 = "/soc/vreg-pm6450-l14";
		L15B = "/soc/vreg-pm6450-l15";
		L15B_E0 = "/soc/vreg-pm6450-l15";
		pm6450_l15 = "/soc/vreg-pm6450-l15";
		L16B = "/soc/vreg-pm6450-l16";
		L16B_E0 = "/soc/vreg-pm6450-l16";
		pm6450_l16 = "/soc/vreg-pm6450-l16";
		L17B = "/soc/vreg-pm6450-l17";
		L17B_E0 = "/soc/vreg-pm6450-l17";
		pm6450_l17 = "/soc/vreg-pm6450-l17";
		L18B = "/soc/vreg-pm6450-l18";
		L18B_E0 = "/soc/vreg-pm6450-l18";
		pm6450_l18 = "/soc/vreg-pm6450-l18";
		L19B = "/soc/reg-pm6450-l19";
		L19B_E0 = "/soc/reg-pm6450-l19";
		pm6450_l19 = "/soc/reg-pm6450-l19";
		L20B = "/soc/vreg-pm6450-l20";
		L20B_E0 = "/soc/vreg-pm6450-l20";
		pm6450_l20 = "/soc/vreg-pm6450-l20";
		L21B = "/soc/vreg-pm6450-l21";
		L21B_E0 = "/soc/vreg-pm6450-l21";
		pm6450_l21 = "/soc/vreg-pm6450-l21";
		L22B = "/soc/vreg-pm6450-l22";
		L22B_E0 = "/soc/vreg-pm6450-l22";
		pm6450_l22 = "/soc/vreg-pm6450-l22";
		L23B = "/soc/vreg-pm6450-l23";
		L23B_E0 = "/soc/vreg-pm6450-l23";
		pm6450_l23 = "/soc/vreg-pm6450-l23";
		L24B = "/soc/vreg-pm6450-l24";
		L24B_E0 = "/soc/vreg-pm6450-l24";
		pm6450_l24 = "/soc/vreg-pm6450-l24";
		L25B = "/soc/vreg-pm6450-l25";
		L25B_E0 = "/soc/vreg-pm6450-l25";
		pm6450_l25 = "/soc/vreg-pm6450-l25";
		L26B = "/soc/vreg-pm6450-l26";
		L26B_E0 = "/soc/vreg-pm6450-l26";
		pm6450_l26 = "/soc/vreg-pm6450-l26";
		L27B = "/soc/vreg-pm6450-l27";
		L27B_E0 = "/soc/vreg-pm6450-l27";
		pm6450_l27 = "/soc/vreg-pm6450-l27";
		L28B = "/soc/vreg-pm6450-l28";
		L28B_E0 = "/soc/vreg-pm6450-l28";
		pm6450_l28 = "/soc/vreg-pm6450-l28";
		VDD_LPI_CX_LEVEL = "/soc/vreg-pm6450-l6-level";
		L6B_LEVEL = "/soc/vreg-pm6450-l6-level";
		L6B_E0_LEVEL = "/soc/vreg-pm6450-l6-level";
		pm6450_l6_level = "/soc/vreg-pm6450-l6-level";
		VDD_LPI_MX_LEVEL = "/soc/vreg-pm6450-l8-level";
		L8B_LEVEL = "/soc/vreg-pm6450-l8-level";
		L8B_E0_LEVEL = "/soc/vreg-pm6450-l8-level";
		pm6450_l8_level = "/soc/vreg-pm6450-l8-level";
		L1M = "/soc/vreg-pm8010m-l1";
		pm8010m_l1 = "/soc/vreg-pm8010m-l1";
		L2M = "/soc/vreg-pm8010m-l2";
		pm8010m_l2 = "/soc/vreg-pm8010m-l2";
		L3M = "/soc/vreg-pm8010m-l3";
		pm8010m_l3 = "/soc/vreg-pm8010m-l3";
		L4M = "/soc/vreg-pm8010m-l4";
		pm8010m_l4 = "/soc/vreg-pm8010m-l4";
		L5M = "/soc/vreg-pm8010m-l5";
		pm8010m_l5 = "/soc/vreg-pm8010m-l5";
		L6M = "/soc/vreg-pm8010m-l6";
		pm8010m_l6 = "/soc/vreg-pm8010m-l6";
		L7M = "/soc/vreg-pm8010m-l7";
		pm8010m_l7 = "/soc/vreg-pm8010m-l7";
		L1E = "/soc/vreg-pm8010e-l1";
		L1E_E0 = "/soc/vreg-pm8010e-l1";
		pm8010e_l1 = "/soc/vreg-pm8010e-l1";
		L2E = "/soc/vreg-pm8010e-l2";
		L2E_E0 = "/soc/vreg-pm8010e-l2";
		pm8010e_l2 = "/soc/vreg-pm8010e-l2";
		L3E = "/soc/vreg-pm8010e-l3";
		L3E_E0 = "/soc/vreg-pm8010e-l3";
		pm8010e_l3 = "/soc/vreg-pm8010e-l3";
		L4E = "/soc/vreg-pm8010e-l4";
		L4E_E0 = "/soc/vreg-pm8010e-l4";
		pm8010e_l4 = "/soc/vreg-pm8010e-l4";
		L5E = "/soc/vreg-pm8010e-l5";
		L5E_E0 = "/soc/vreg-pm8010e-l5";
		pm8010e_l5 = "/soc/vreg-pm8010e-l5";
		L6E = "/soc/vreg-pm8010e-l6";
		L6E_E0 = "/soc/vreg-pm8010e-l6";
		pm8010e_l6 = "/soc/vreg-pm8010e-l6";
		L7E = "/soc/vreg-pm8010e-l7";
		L7E_E0 = "/soc/vreg-pm8010e-l7";
		pm8010e_l7 = "/soc/vreg-pm8010e-l7";
	};
};
